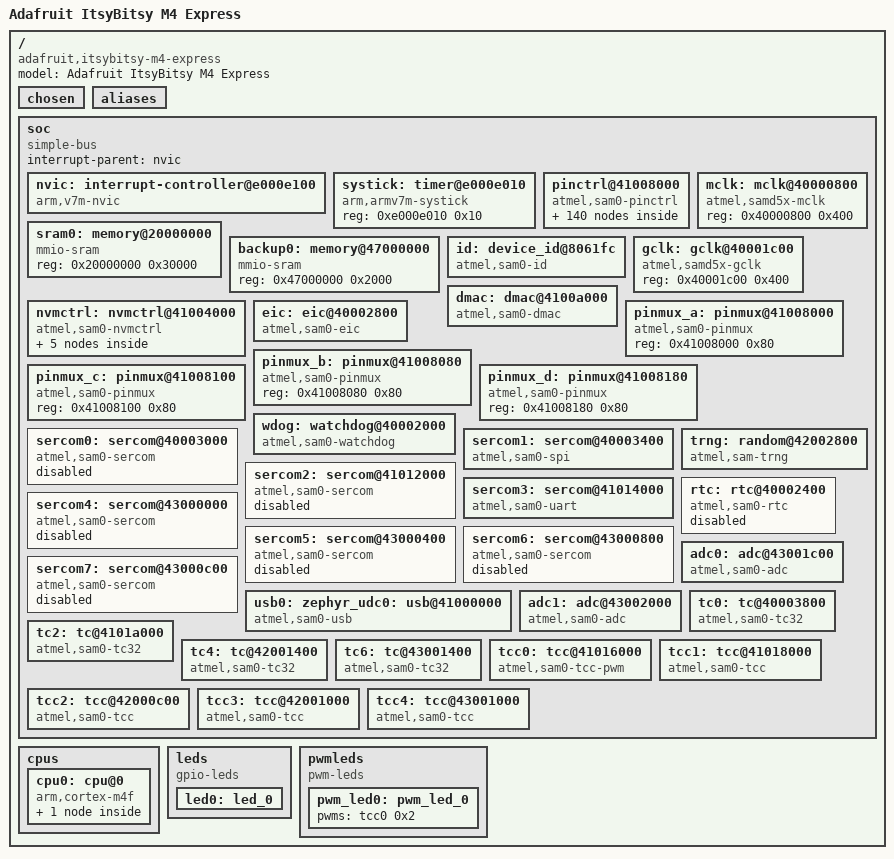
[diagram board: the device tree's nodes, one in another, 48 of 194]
/dts-v1/;

/ {
	#address-cells = < 0x1 >;
	#size-cells = < 0x1 >;
	model = "Adafruit ItsyBitsy M4 Express";
	compatible = "adafruit,itsybitsy-m4-express";
	chosen {
		zephyr,flash-controller = &nvmctrl;
		zephyr,entropy = &trng;
		zephyr,console = &sercom3;
		zephyr,shell-uart = &sercom3;
		zephyr,sram = &sram0;
		zephyr,flash = &flash0;
		zephyr,code-partition = &code_partition;
	};
	aliases {
		adc-0 = &adc0;
		adc-1 = &adc1;
		port-a = &porta;
		port-b = &portb;
		port-c = &portc;
		port-d = &portd;
		sercom-0 = &sercom0;
		sercom-1 = &sercom1;
		sercom-2 = &sercom2;
		sercom-3 = &sercom3;
		sercom-4 = &sercom4;
		sercom-5 = &sercom5;
		sercom-6 = &sercom6;
		sercom-7 = &sercom7;
		tc-0 = &tc0;
		tc-2 = &tc2;
		tc-4 = &tc4;
		tc-6 = &tc6;
		tcc-0 = &tcc0;
		tcc-1 = &tcc1;
		tcc-2 = &tcc2;
		tcc-3 = &tcc3;
		tcc-4 = &tcc4;
		watchdog0 = &wdog;
		led0 = &led0;
		pwm-led0 = &pwm_led0;
		pwm-0 = &tcc0;
	};
	soc {
		#address-cells = < 0x1 >;
		#size-cells = < 0x1 >;
		compatible = "simple-bus";
		interrupt-parent = < &nvic >;
		ranges;
		nvic: interrupt-controller@e000e100 {
			#address-cells = < 0x1 >;
			compatible = "arm,v7m-nvic";
			reg = < 0xe000e100 0xc00 >;
			interrupt-controller;
			#interrupt-cells = < 0x2 >;
			arm,num-irq-priority-bits = < 0x3 >;
			phandle = < 0x1 >;
		};
		systick: timer@e000e010 {
			compatible = "arm,armv7m-systick";
			reg = < 0xe000e010 0x10 >;
		};
		pinctrl@41008000 {
			compatible = "atmel,sam0-pinctrl";
			#address-cells = < 0x1 >;
			#size-cells = < 0x1 >;
			ranges = < 0x41008000 0x41008000 0x200 >;
			pa8c_sercom0_pad0: pa8c_sercom0_pad0 {
				atmel,pins = < &porta 0x8 0x2 >;
				pinmux-enable;
			};
			pa9c_sercom0_pad1: pa9c_sercom0_pad1 {
				atmel,pins = < &porta 0x9 0x2 >;
				pinmux-enable;
			};
			pa10c_sercom0_pad2: pa10c_sercom0_pad2 {
				atmel,pins = < &porta 0xa 0x2 >;
				pinmux-enable;
			};
			pa11c_sercom0_pad3: pa11c_sercom0_pad3 {
				atmel,pins = < &porta 0xb 0x2 >;
				pinmux-enable;
			};
			pb24c_sercom0_pad0: pb24c_sercom0_pad0 {
				atmel,pins = < &portb 0x18 0x2 >;
				pinmux-enable;
			};
			pb25c_sercom0_pad1: pb25c_sercom0_pad1 {
				atmel,pins = < &portb 0x19 0x2 >;
				pinmux-enable;
			};
			pc24c_sercom0_pad2: pc24c_sercom0_pad2 {
				atmel,pins = < &portc 0x18 0x2 >;
				pinmux-enable;
			};
			pc25c_sercom0_pad3: pc25c_sercom0_pad3 {
				atmel,pins = < &portc 0x19 0x2 >;
				pinmux-enable;
			};
			pa4d_sercom0_pad0: pa4d_sercom0_pad0 {
				atmel,pins = < &porta 0x4 0x3 >;
				pinmux-enable;
			};
			pa5d_sercom0_pad1: pa5d_sercom0_pad1 {
				atmel,pins = < &porta 0x5 0x3 >;
				pinmux-enable;
			};
			pa6d_sercom0_pad2: pa6d_sercom0_pad2 {
				atmel,pins = < &porta 0x6 0x3 >;
				pinmux-enable;
			};
			pa7d_sercom0_pad3: pa7d_sercom0_pad3 {
				atmel,pins = < &porta 0x7 0x3 >;
				pinmux-enable;
			};
			pc17d_sercom0_pad0: pc17d_sercom0_pad0 {
				atmel,pins = < &portc 0x11 0x3 >;
				pinmux-enable;
			};
			pc16d_sercom0_pad1: pc16d_sercom0_pad1 {
				atmel,pins = < &portc 0x10 0x3 >;
				pinmux-enable;
			};
			pc18d_sercom0_pad2: pc18d_sercom0_pad2 {
				atmel,pins = < &portc 0x12 0x3 >;
				pinmux-enable;
			};
			pc19d_sercom0_pad3: pc19d_sercom0_pad3 {
				atmel,pins = < &portc 0x13 0x3 >;
				pinmux-enable;
			};
			pa16c_sercom1_pad0: pa16c_sercom1_pad0 {
				atmel,pins = < &porta 0x10 0x2 >;
				pinmux-enable;
			};
			pa17c_sercom1_pad1: pa17c_sercom1_pad1 {
				atmel,pins = < &porta 0x11 0x2 >;
				pinmux-enable;
			};
			pa18c_sercom1_pad2: pa18c_sercom1_pad2 {
				atmel,pins = < &porta 0x12 0x2 >;
				pinmux-enable;
			};
			pa19c_sercom1_pad3: pa19c_sercom1_pad3 {
				atmel,pins = < &porta 0x13 0x2 >;
				pinmux-enable;
			};
			pc22c_sercom1_pad0: pc22c_sercom1_pad0 {
				atmel,pins = < &portc 0x16 0x2 >;
				pinmux-enable;
			};
			pc23c_sercom1_pad1: pc23c_sercom1_pad1 {
				atmel,pins = < &portc 0x17 0x2 >;
				pinmux-enable;
			};
			pd20c_sercom1_pad2: pd20c_sercom1_pad2 {
				atmel,pins = < &portd 0x14 0x2 >;
				pinmux-enable;
			};
			pd21c_sercom1_pad3: pd21c_sercom1_pad3 {
				atmel,pins = < &portd 0x15 0x2 >;
				pinmux-enable;
			};
			pc27c_sercom1_pad0: pc27c_sercom1_pad0 {
				atmel,pins = < &portc 0x1b 0x2 >;
				pinmux-enable;
			};
			pc28c_sercom1_pad1: pc28c_sercom1_pad1 {
				atmel,pins = < &portc 0x1c 0x2 >;
				pinmux-enable;
			};
			pb22c_sercom1_pad2: pb22c_sercom1_pad2 {
				atmel,pins = < &portb 0x16 0x2 >;
				pinmux-enable;
			};
			pb23c_sercom1_pad3: pb23c_sercom1_pad3 {
				atmel,pins = < &portb 0x17 0x2 >;
				pinmux-enable;
			};
			pa0d_sercom1_pad0: pa0d_sercom1_pad0 {
				atmel,pins = < &porta 0x0 0x3 >;
				pinmux-enable;
			};
			pa1d_sercom1_pad1: pa1d_sercom1_pad1 {
				atmel,pins = < &porta 0x1 0x3 >;
				pinmux-enable;
			};
			pa30d_sercom1_pad2: pa30d_sercom1_pad2 {
				atmel,pins = < &porta 0x1e 0x3 >;
				pinmux-enable;
			};
			pa31d_sercom1_pad3: pa31d_sercom1_pad3 {
				atmel,pins = < &porta 0x1f 0x3 >;
				pinmux-enable;
			};
			pa12c_sercom2_pad0: pa12c_sercom2_pad0 {
				atmel,pins = < &porta 0xc 0x2 >;
				pinmux-enable;
			};
			pa13c_sercom2_pad1: pa13c_sercom2_pad1 {
				atmel,pins = < &porta 0xd 0x2 >;
				pinmux-enable;
			};
			pa14c_sercom2_pad2: pa14c_sercom2_pad2 {
				atmel,pins = < &porta 0xe 0x2 >;
				pinmux-enable;
			};
			pa15c_sercom2_pad3: pa15c_sercom2_pad3 {
				atmel,pins = < &porta 0xf 0x2 >;
				pinmux-enable;
			};
			pb26c_sercom2_pad0: pb26c_sercom2_pad0 {
				atmel,pins = < &portb 0x1a 0x2 >;
				pinmux-enable;
			};
			pb27c_sercom2_pad1: pb27c_sercom2_pad1 {
				atmel,pins = < &portb 0x1b 0x2 >;
				pinmux-enable;
			};
			pb28c_sercom2_pad2: pb28c_sercom2_pad2 {
				atmel,pins = < &portb 0x1c 0x2 >;
				pinmux-enable;
			};
			pb29c_sercom2_pad3: pb29c_sercom2_pad3 {
				atmel,pins = < &portb 0x1d 0x2 >;
				pinmux-enable;
			};
			pa8d_sercom2_pad0: pa8d_sercom2_pad0 {
				atmel,pins = < &porta 0x8 0x3 >;
				pinmux-enable;
			};
			pa9d_sercom2_pad1: pa9d_sercom2_pad1 {
				atmel,pins = < &porta 0x9 0x3 >;
				pinmux-enable;
			};
			pa10d_sercom2_pad2: pa10d_sercom2_pad2 {
				atmel,pins = < &porta 0xa 0x3 >;
				pinmux-enable;
			};
			pa11d_sercom2_pad3: pa11d_sercom2_pad3 {
				atmel,pins = < &porta 0xb 0x3 >;
				pinmux-enable;
			};
			pb24d_sercom2_pad0: pb24d_sercom2_pad0 {
				atmel,pins = < &portb 0x18 0x3 >;
				pinmux-enable;
			};
			pb25d_sercom2_pad1: pb25d_sercom2_pad1 {
				atmel,pins = < &portb 0x19 0x3 >;
				pinmux-enable;
			};
			pc24d_sercom2_pad2: pc24d_sercom2_pad2 {
				atmel,pins = < &portc 0x18 0x3 >;
				pinmux-enable;
			};
			pc25d_sercom2_pad3: pc25d_sercom2_pad3 {
				atmel,pins = < &portc 0x19 0x3 >;
				pinmux-enable;
			};
			pa22c_sercom3_pad0: pa22c_sercom3_pad0 {
				atmel,pins = < &porta 0x16 0x2 >;
				pinmux-enable;
			};
			pa23c_sercom3_pad1: pa23c_sercom3_pad1 {
				atmel,pins = < &porta 0x17 0x2 >;
				pinmux-enable;
			};
			pa24c_sercom3_pad2: pa24c_sercom3_pad2 {
				atmel,pins = < &porta 0x18 0x2 >;
				pinmux-enable;
			};
			pa25c_sercom3_pad3: pa25c_sercom3_pad3 {
				atmel,pins = < &porta 0x19 0x2 >;
				pinmux-enable;
			};
			pb20c_sercom3_pad0: pb20c_sercom3_pad0 {
				atmel,pins = < &portb 0x14 0x2 >;
				pinmux-enable;
			};
			pb21c_sercom3_pad1: pb21c_sercom3_pad1 {
				atmel,pins = < &portb 0x15 0x2 >;
				pinmux-enable;
			};
			pa20d_sercom3_pad2: pa20d_sercom3_pad2 {
				atmel,pins = < &porta 0x14 0x3 >;
				pinmux-enable;
			};
			pa21d_sercom3_pad3: pa21d_sercom3_pad3 {
				atmel,pins = < &porta 0x15 0x3 >;
				pinmux-enable;
			};
			pa17d_sercom3_pad0: pa17d_sercom3_pad0 {
				atmel,pins = < &porta 0x11 0x3 >;
				pinmux-enable;
				phandle = < 0x9 >;
			};
			pa16d_sercom3_pad1: pa16d_sercom3_pad1 {
				atmel,pins = < &porta 0x10 0x3 >;
				pinmux-enable;
				phandle = < 0x8 >;
			};
			pa18d_sercom3_pad2: pa18d_sercom3_pad2 {
				atmel,pins = < &porta 0x12 0x3 >;
				pinmux-enable;
			};
			pa19d_sercom3_pad3: pa19d_sercom3_pad3 {
				atmel,pins = < &porta 0x13 0x3 >;
				pinmux-enable;
			};
			pc23d_sercom3_pad0: pc23d_sercom3_pad0 {
				atmel,pins = < &portc 0x17 0x3 >;
				pinmux-enable;
			};
			pc22d_sercom3_pad1: pc22d_sercom3_pad1 {
				atmel,pins = < &portc 0x16 0x3 >;
				pinmux-enable;
			};
			pd20d_sercom3_pad2: pd20d_sercom3_pad2 {
				atmel,pins = < &portd 0x14 0x3 >;
				pinmux-enable;
			};
			pd21d_sercom3_pad3: pd21d_sercom3_pad3 {
				atmel,pins = < &portd 0x15 0x3 >;
				pinmux-enable;
			};
			pb12c_sercom4_pad0: pb12c_sercom4_pad0 {
				atmel,pins = < &portb 0xc 0x2 >;
				pinmux-enable;
			};
			pb13c_sercom4_pad1: pb13c_sercom4_pad1 {
				atmel,pins = < &portb 0xd 0x2 >;
				pinmux-enable;
			};
			pb14c_sercom4_pad2: pb14c_sercom4_pad2 {
				atmel,pins = < &portb 0xe 0x2 >;
				pinmux-enable;
			};
			pb15c_sercom4_pad3: pb15c_sercom4_pad3 {
				atmel,pins = < &portb 0xf 0x2 >;
				pinmux-enable;
			};
			pb8d_sercom4_pad0: pb8d_sercom4_pad0 {
				atmel,pins = < &portb 0x8 0x3 >;
				pinmux-enable;
			};
			pb9d_sercom4_pad1: pb9d_sercom4_pad1 {
				atmel,pins = < &portb 0x9 0x3 >;
				pinmux-enable;
			};
			pb10d_sercom4_pad2: pb10d_sercom4_pad2 {
				atmel,pins = < &portb 0xa 0x3 >;
				pinmux-enable;
			};
			pb11d_sercom4_pad3: pb11d_sercom4_pad3 {
				atmel,pins = < &portb 0xb 0x3 >;
				pinmux-enable;
			};
			pa13d_sercom4_pad0: pa13d_sercom4_pad0 {
				atmel,pins = < &porta 0xd 0x3 >;
				pinmux-enable;
			};
			pa12d_sercom4_pad1: pa12d_sercom4_pad1 {
				atmel,pins = < &porta 0xc 0x3 >;
				pinmux-enable;
			};
			pa14d_sercom4_pad2: pa14d_sercom4_pad2 {
				atmel,pins = < &porta 0xe 0x3 >;
				pinmux-enable;
			};
			pa15d_sercom4_pad3: pa15d_sercom4_pad3 {
				atmel,pins = < &porta 0xf 0x3 >;
				pinmux-enable;
			};
			pb27d_sercom4_pad0: pb27d_sercom4_pad0 {
				atmel,pins = < &portb 0x1b 0x3 >;
				pinmux-enable;
			};
			pb26d_sercom4_pad1: pb26d_sercom4_pad1 {
				atmel,pins = < &portb 0x1a 0x3 >;
				pinmux-enable;
			};
			pb28d_sercom4_pad2: pb28d_sercom4_pad2 {
				atmel,pins = < &portb 0x1c 0x3 >;
				pinmux-enable;
			};
			pb29d_sercom4_pad3: pb29d_sercom4_pad3 {
				atmel,pins = < &portb 0x1d 0x3 >;
				pinmux-enable;
			};
			pb16c_sercom5_pad0: pb16c_sercom5_pad0 {
				atmel,pins = < &portb 0x10 0x2 >;
				pinmux-enable;
			};
			pb17c_sercom5_pad1: pb17c_sercom5_pad1 {
				atmel,pins = < &portb 0x11 0x2 >;
				pinmux-enable;
			};
			pb18c_sercom5_pad2: pb18c_sercom5_pad2 {
				atmel,pins = < &portb 0x12 0x2 >;
				pinmux-enable;
			};
			pb19c_sercom5_pad3: pb19c_sercom5_pad3 {
				atmel,pins = < &portb 0x13 0x2 >;
				pinmux-enable;
			};
			pa23d_sercom5_pad0: pa23d_sercom5_pad0 {
				atmel,pins = < &porta 0x17 0x3 >;
				pinmux-enable;
			};
			pa22d_sercom5_pad1: pa22d_sercom5_pad1 {
				atmel,pins = < &porta 0x16 0x3 >;
				pinmux-enable;
			};
			pa20c_sercom5_pad2: pa20c_sercom5_pad2 {
				atmel,pins = < &porta 0x14 0x2 >;
				pinmux-enable;
			};
			pa21c_sercom5_pad3: pa21c_sercom5_pad3 {
				atmel,pins = < &porta 0x15 0x2 >;
				pinmux-enable;
			};
			pa24d_sercom5_pad2: pa24d_sercom5_pad2 {
				atmel,pins = < &porta 0x18 0x3 >;
				pinmux-enable;
			};
			pa25d_sercom5_pad3: pa25d_sercom5_pad3 {
				atmel,pins = < &porta 0x19 0x3 >;
				pinmux-enable;
			};
			pb22d_sercom5_pad2: pb22d_sercom5_pad2 {
				atmel,pins = < &portb 0x16 0x3 >;
				pinmux-enable;
			};
			pb23d_sercom5_pad3: pb23d_sercom5_pad3 {
				atmel,pins = < &portb 0x17 0x3 >;
				pinmux-enable;
			};
			pb31d_sercom5_pad0: pb31d_sercom5_pad0 {
				atmel,pins = < &portb 0x1f 0x3 >;
				pinmux-enable;
			};
			pb30d_sercom5_pad1: pb30d_sercom5_pad1 {
				atmel,pins = < &portb 0x1e 0x3 >;
				pinmux-enable;
			};
			pb0d_sercom5_pad2: pb0d_sercom5_pad2 {
				atmel,pins = < &portb 0x0 0x3 >;
				pinmux-enable;
			};
			pb1d_sercom5_pad3: pb1d_sercom5_pad3 {
				atmel,pins = < &portb 0x1 0x3 >;
				pinmux-enable;
			};
			pb2d_sercom5_pad0: pb2d_sercom5_pad0 {
				atmel,pins = < &portb 0x2 0x3 >;
				pinmux-enable;
			};
			pb3d_sercom5_pad1: pb3d_sercom5_pad1 {
				atmel,pins = < &portb 0x3 0x3 >;
				pinmux-enable;
			};
			pc16c_sercom6_pad0: pc16c_sercom6_pad0 {
				atmel,pins = < &portc 0x10 0x2 >;
				pinmux-enable;
			};
			pc17c_sercom6_pad1: pc17c_sercom6_pad1 {
				atmel,pins = < &portc 0x11 0x2 >;
				pinmux-enable;
			};
			pc18c_sercom6_pad2: pc18c_sercom6_pad2 {
				atmel,pins = < &portc 0x12 0x2 >;
				pinmux-enable;
			};
			pc19c_sercom6_pad3: pc19c_sercom6_pad3 {
				atmel,pins = < &portc 0x13 0x2 >;
				pinmux-enable;
			};
			pc4c_sercom6_pad0: pc4c_sercom6_pad0 {
				atmel,pins = < &portc 0x4 0x2 >;
				pinmux-enable;
			};
			pc5c_sercom6_pad1: pc5c_sercom6_pad1 {
				atmel,pins = < &portc 0x5 0x2 >;
				pinmux-enable;
			};
			pc6c_sercom6_pad2: pc6c_sercom6_pad2 {
				atmel,pins = < &portc 0x6 0x2 >;
				pinmux-enable;
			};
			pc7c_sercom6_pad3: pc7c_sercom6_pad3 {
				atmel,pins = < &portc 0x7 0x2 >;
				pinmux-enable;
			};
			pd9d_sercom6_pad0: pd9d_sercom6_pad0 {
				atmel,pins = < &portd 0x9 0x3 >;
				pinmux-enable;
			};
			pd8d_sercom6_pad1: pd8d_sercom6_pad1 {
				atmel,pins = < &portd 0x8 0x3 >;
				pinmux-enable;
			};
			pd10d_sercom6_pad2: pd10d_sercom6_pad2 {
				atmel,pins = < &portd 0xa 0x3 >;
				pinmux-enable;
			};
			pd11d_sercom6_pad3: pd11d_sercom6_pad3 {
				atmel,pins = < &portd 0xb 0x3 >;
				pinmux-enable;
			};
			pc13d_sercom6_pad0: pc13d_sercom6_pad0 {
				atmel,pins = < &portc 0xd 0x3 >;
				pinmux-enable;
			};
			pc12d_sercom6_pad1: pc12d_sercom6_pad1 {
				atmel,pins = < &portc 0xc 0x3 >;
				pinmux-enable;
			};
			pc14d_sercom6_pad2: pc14d_sercom6_pad2 {
				atmel,pins = < &portc 0xe 0x3 >;
				pinmux-enable;
			};
			pc15d_sercom6_pad3: pc15d_sercom6_pad3 {
				atmel,pins = < &portc 0xf 0x3 >;
				pinmux-enable;
			};
			pc10c_sercom6_pad2: pc10c_sercom6_pad2 {
				atmel,pins = < &portc 0xa 0x2 >;
				pinmux-enable;
			};
			pc11c_sercom6_pad3: pc11c_sercom6_pad3 {
				atmel,pins = < &portc 0xb 0x2 >;
				pinmux-enable;
			};
			pc12c_sercom7_pad0: pc12c_sercom7_pad0 {
				atmel,pins = < &portc 0xc 0x2 >;
				pinmux-enable;
			};
			pc13c_sercom7_pad1: pc13c_sercom7_pad1 {
				atmel,pins = < &portc 0xd 0x2 >;
				pinmux-enable;
			};
			pc14c_sercom7_pad2: pc14c_sercom7_pad2 {
				atmel,pins = < &portc 0xe 0x2 >;
				pinmux-enable;
			};
			pc15c_sercom7_pad3: pc15c_sercom7_pad3 {
				atmel,pins = < &portc 0xf 0x2 >;
				pinmux-enable;
			};
			pd8c_sercom7_pad0: pd8c_sercom7_pad0 {
				atmel,pins = < &portd 0x8 0x2 >;
				pinmux-enable;
			};
			pd9c_sercom7_pad1: pd9c_sercom7_pad1 {
				atmel,pins = < &portd 0x9 0x2 >;
				pinmux-enable;
			};
			pd10c_sercom7_pad2: pd10c_sercom7_pad2 {
				atmel,pins = < &portd 0xa 0x2 >;
				pinmux-enable;
			};
			pd11c_sercom7_pad3: pd11c_sercom7_pad3 {
				atmel,pins = < &portd 0xb 0x2 >;
				pinmux-enable;
			};
			pc12d_sercom7_pad0: pc12d_sercom7_pad0 {
				atmel,pins = < &portc 0xc 0x3 >;
				pinmux-enable;
			};
			pc13d_sercom7_pad1: pc13d_sercom7_pad1 {
				atmel,pins = < &portc 0xd 0x3 >;
				pinmux-enable;
			};
			pc10d_sercom7_pad2: pc10d_sercom7_pad2 {
				atmel,pins = < &portc 0xa 0x3 >;
				pinmux-enable;
			};
			pc11d_sercom7_pad3: pc11d_sercom7_pad3 {
				atmel,pins = < &portc 0xb 0x3 >;
				pinmux-enable;
			};
			pb21d_sercom7_pad0: pb21d_sercom7_pad0 {
				atmel,pins = < &portb 0x15 0x3 >;
				pinmux-enable;
			};
			pb20d_sercom7_pad1: pb20d_sercom7_pad1 {
				atmel,pins = < &portb 0x14 0x3 >;
				pinmux-enable;
			};
			pb18d_sercom7_pad2: pb18d_sercom7_pad2 {
				atmel,pins = < &portb 0x12 0x3 >;
				pinmux-enable;
			};
			pb19d_sercom7_pad3: pb19d_sercom7_pad3 {
				atmel,pins = < &portb 0x13 0x3 >;
				pinmux-enable;
			};
			pb30d_sercom7_pad0: pb30d_sercom7_pad0 {
				atmel,pins = < &portb 0x1e 0x3 >;
				pinmux-enable;
			};
			pb31d_sercom7_pad1: pb31d_sercom7_pad1 {
				atmel,pins = < &portb 0x1f 0x3 >;
				pinmux-enable;
			};
			pa30d_sercom7_pad2: pa30d_sercom7_pad2 {
				atmel,pins = < &porta 0x1e 0x3 >;
				pinmux-enable;
			};
			pa31d_sercom7_pad3: pa31d_sercom7_pad3 {
				atmel,pins = < &porta 0x1f 0x3 >;
				pinmux-enable;
			};
			porta: gpio@41008000 {
				compatible = "atmel,sam0-gpio";
				reg = < 0x41008000 0x80 >;
				label = "PORTA";
				gpio-controller;
				#gpio-cells = < 0x2 >;
				#atmel,pin-cells = < 0x2 >;
				phandle = < 0x2 >;
			};
			portb: gpio@41008080 {
				compatible = "atmel,sam0-gpio";
				reg = < 0x41008080 0x80 >;
				label = "PORTB";
				gpio-controller;
				#gpio-cells = < 0x2 >;
				#atmel,pin-cells = < 0x2 >;
				phandle = < 0x3 >;
			};
			portc: gpio@41008100 {
				compatible = "atmel,sam0-gpio";
				reg = < 0x41008100 0x80 >;
				label = "PORTC";
				gpio-controller;
				#gpio-cells = < 0x2 >;
				#atmel,pin-cells = < 0x2 >;
				phandle = < 0x4 >;
			};
			portd: gpio@41008180 {
				compatible = "atmel,sam0-gpio";
				reg = < 0x41008180 0x80 >;
				label = "PORTD";
				gpio-controller;
				#gpio-cells = < 0x2 >;
				#atmel,pin-cells = < 0x2 >;
				phandle = < 0x5 >;
			};
		};
		sram0: memory@20000000 {
			compatible = "mmio-sram";
			reg = < 0x20000000 0x30000 >;
		};
		backup0: memory@47000000 {
			compatible = "mmio-sram";
			reg = < 0x47000000 0x2000 >;
		};
		id: device_id@8061fc {
			compatible = "atmel,sam0-id";
			reg = < 0x8061fc 0x4 >, < 0x806010 0x4 >, < 0x806014 0x4 >, < 0x806018 0x4 >;
		};
		mclk: mclk@40000800 {
			compatible = "atmel,samd5x-mclk";
			reg = < 0x40000800 0x400 >;
			#clock-cells = < 0x2 >;
			phandle = < 0x7 >;
		};
		gclk: gclk@40001c00 {
			compatible = "atmel,samd5x-gclk";
			reg = < 0x40001c00 0x400 >;
			#clock-cells = < 0x1 >;
			phandle = < 0x6 >;
		};
		nvmctrl: nvmctrl@41004000 {
			compatible = "atmel,sam0-nvmctrl";
			label = "FLASH_CTRL";
			reg = < 0x41004000 0x22 >;
			interrupts = < 0x1d 0x0 >, < 0x1e 0x0 >;
			lock-regions = < 0x20 >;
			#address-cells = < 0x1 >;
			#size-cells = < 0x1 >;
			flash0: flash@0 {
				compatible = "soc-nv-flash";
				label = "FLASH_0";
				write-block-size = < 0x8 >;
				reg = < 0x0 0x80000 >;
				partitions {
					compatible = "fixed-partitions";
					#address-cells = < 0x1 >;
					#size-cells = < 0x1 >;
					boot_partition: partition@0 {
						label = "uf2";
						reg = < 0x0 0x4000 >;
						read-only;
					};
					code_partition: partition@4000 {
						label = "code";
						reg = < 0x4000 0x78000 >;
						read-only;
					};
					storage_partition: partition@7c000 {
						label = "storage";
						reg = < 0x7c000 0x4000 >;
					};
				};
			};
		};
		dmac: dmac@4100a000 {
			compatible = "atmel,sam0-dmac";
			reg = < 0x4100a000 0x50 >;
			interrupts = < 0x1f 0x0 >, < 0x20 0x0 >, < 0x21 0x0 >, < 0x22 0x0 >, < 0x23 0x0 >;
			label = "DMA_0";
			#dma-cells = < 0x2 >;
			status = "okay";
		};
		eic: eic@40002800 {
			compatible = "atmel,sam0-eic";
			reg = < 0x40002800 0x38 >;
			interrupts = < 0xc 0x0 >, < 0xd 0x0 >, < 0xe 0x0 >, < 0xf 0x0 >, < 0x10 0x0 >, < 0x11 0x0 >, < 0x12 0x0 >, < 0x13 0x0 >, < 0x14 0x0 >, < 0x15 0x0 >, < 0x16 0x0 >, < 0x17 0x0 >, < 0x18 0x0 >, < 0x19 0x0 >, < 0x1a 0x0 >, < 0x1b 0x0 >;
			label = "EIC";
		};
		pinmux_a: pinmux@41008000 {
			compatible = "atmel,sam0-pinmux";
			reg = < 0x41008000 0x80 >;
		};
		pinmux_b: pinmux@41008080 {
			compatible = "atmel,sam0-pinmux";
			reg = < 0x41008080 0x80 >;
		};
		pinmux_c: pinmux@41008100 {
			compatible = "atmel,sam0-pinmux";
			reg = < 0x41008100 0x80 >;
		};
		pinmux_d: pinmux@41008180 {
			compatible = "atmel,sam0-pinmux";
			reg = < 0x41008180 0x80 >;
		};
		wdog: watchdog@40002000 {
			compatible = "atmel,sam0-watchdog";
			reg = < 0x40002000 0xd >;
			interrupts = < 0xa 0x0 >;
			label = "WATCHDOG_0";
		};
		sercom0: sercom@40003000 {
			compatible = "atmel,sam0-sercom";
			reg = < 0x40003000 0x40 >;
			interrupts = < 0x2e 0x0 >, < 0x2f 0x0 >, < 0x30 0x0 >, < 0x31 0x0 >;
			status = "disabled";
			label = "SERCOM0";
			clocks = < &gclk 0x7 >, < &mclk 0x14 0xc >;
			clock-names = "GCLK", "MCLK";
		};
		sercom1: sercom@40003400 {
			compatible = "atmel,sam0-spi";
			reg = < 0x40003400 0x40 >;
			interrupts = < 0x32 0x0 >, < 0x33 0x0 >, < 0x34 0x0 >, < 0x35 0x0 >;
			status = "okay";
			label = "SERCOM1";
			clocks = < &gclk 0x8 >, < &mclk 0x14 0xd >;
			clock-names = "GCLK", "MCLK";
			dipo = < 0x3 >;
			dopo = < 0x0 >;
			#address-cells = < 0x1 >;
			#size-cells = < 0x0 >;
		};
		sercom2: sercom@41012000 {
			compatible = "atmel,sam0-sercom";
			reg = < 0x41012000 0x40 >;
			interrupts = < 0x36 0x0 >, < 0x37 0x0 >, < 0x38 0x0 >, < 0x39 0x0 >;
			status = "disabled";
			label = "SERCOM2";
			clocks = < &gclk 0x17 >, < &mclk 0x18 0x9 >;
			clock-names = "GCLK", "MCLK";
		};
		sercom3: sercom@41014000 {
			compatible = "atmel,sam0-uart";
			reg = < 0x41014000 0x40 >;
			interrupts = < 0x3a 0x0 >, < 0x3b 0x0 >, < 0x3c 0x0 >, < 0x3d 0x0 >;
			status = "okay";
			label = "SERCOM3";
			clocks = < &gclk 0x18 >, < &mclk 0x18 0xa >;
			clock-names = "GCLK", "MCLK";
			current-speed = < 0x1c200 >;
			rxpo = < 0x1 >;
			txpo = < 0x0 >;
			pinctrl-0 = < &pa16d_sercom3_pad1 &pa17d_sercom3_pad0 >;
		};
		sercom4: sercom@43000000 {
			compatible = "atmel,sam0-sercom";
			reg = < 0x43000000 0x40 >;
			interrupts = < 0x3e 0x0 >, < 0x3f 0x0 >, < 0x40 0x0 >, < 0x41 0x0 >;
			status = "disabled";
			label = "SERCOM4";
			clocks = < &gclk 0x22 >, < &mclk 0x20 0x0 >;
			clock-names = "GCLK", "MCLK";
		};
		sercom5: sercom@43000400 {
			compatible = "atmel,sam0-sercom";
			reg = < 0x43000400 0x40 >;
			interrupts = < 0x42 0x0 >, < 0x43 0x0 >, < 0x44 0x0 >, < 0x45 0x0 >;
			status = "disabled";
			label = "SERCOM5";
			clocks = < &gclk 0x23 >, < &mclk 0x20 0x1 >;
			clock-names = "GCLK", "MCLK";
		};
		sercom6: sercom@43000800 {
			compatible = "atmel,sam0-sercom";
			reg = < 0x43000800 0x40 >;
			interrupts = < 0x46 0x0 >, < 0x47 0x0 >, < 0x48 0x0 >, < 0x49 0x0 >;
			status = "disabled";
			label = "SERCOM6";
			clocks = < &gclk 0x24 >, < &mclk 0x20 0x2 >;
			clock-names = "GCLK", "MCLK";
		};
		sercom7: sercom@43000c00 {
			compatible = "atmel,sam0-sercom";
			reg = < 0x43000c00 0x40 >;
			interrupts = < 0x4a 0x0 >, < 0x4b 0x0 >, < 0x4c 0x0 >, < 0x4d 0x0 >;
			status = "disabled";
			label = "SERCOM7";
			clocks = < &gclk 0x25 >, < &mclk 0x20 0x3 >;
			clock-names = "GCLK", "MCLK";
		};
		usb0: zephyr_udc0: usb@41000000 {
			compatible = "atmel,sam0-usb";
			status = "okay";
			reg = < 0x41000000 0x1000 >;
			interrupts = < 0x50 0x0 >, < 0x51 0x0 >, < 0x52 0x0 >, < 0x53 0x0 >;
			num-bidir-endpoints = < 0x8 >;
			label = "USB0";
		};
		trng: random@42002800 {
			compatible = "atmel,sam-trng";
			reg = < 0x42002800 0x1e >;
			peripheral-id = < 0x0 >;
			interrupts = < 0x83 0x0 >;
			label = "ENTROPY_0";
		};
		rtc: rtc@40002400 {
			compatible = "atmel,sam0-rtc";
			reg = < 0x40002400 0x1c >;
			interrupts = < 0xb 0x0 >;
			clock-generator = < 0x0 >;
			status = "disabled";
			label = "RTC";
		};
		adc0: adc@43001c00 {
			compatible = "atmel,sam0-adc";
			reg = < 0x43001c00 0x4a >;
			interrupts = < 0x76 0x0 >, < 0x77 0x0 >;
			interrupt-names = "overrun", "resrdy";
			label = "ADC_0";
			gclk = < 0x2 >;
			prescaler = < 0x4 >;
			#io-channel-cells = < 0x1 >;
			clocks = < &gclk 0x28 >, < &mclk 0x20 0x7 >;
			clock-names = "GCLK", "MCLK";
			calib-offset = < 0x0 >;
		};
		adc1: adc@43002000 {
			compatible = "atmel,sam0-adc";
			reg = < 0x43002000 0x4a >;
			interrupts = < 0x78 0x0 >, < 0x79 0x0 >;
			interrupt-names = "overrun", "resrdy";
			label = "ADC_1";
			gclk = < 0x2 >;
			prescaler = < 0x4 >;
			#io-channel-cells = < 0x1 >;
			clocks = < &gclk 0x29 >, < &mclk 0x20 0x8 >;
			clock-names = "GCLK", "MCLK";
			calib-offset = < 0xe >;
		};
		tc0: tc@40003800 {
			compatible = "atmel,sam0-tc32";
			reg = < 0x40003800 0x34 >;
			interrupts = < 0x6b 0x0 >;
			label = "TIMER_0";
			clocks = < &gclk 0x9 >, < &mclk 0x14 0xe >;
			clock-names = "GCLK", "MCLK";
		};
		tc2: tc@4101a000 {
			compatible = "atmel,sam0-tc32";
			reg = < 0x4101a000 0x34 >;
			interrupts = < 0x6d 0x0 >;
			label = "TIMER_2";
			clocks = < &gclk 0x1a >, < &mclk 0x18 0xd >;
			clock-names = "GCLK", "MCLK";
		};
		tc4: tc@42001400 {
			compatible = "atmel,sam0-tc32";
			reg = < 0x42001400 0x34 >;
			interrupts = < 0x6f 0x0 >;
			label = "TIMER_4";
			clocks = < &gclk 0x1e >, < &mclk 0x1c 0x5 >;
			clock-names = "GCLK", "MCLK";
		};
		tc6: tc@43001400 {
			compatible = "atmel,sam0-tc32";
			reg = < 0x43001400 0x34 >;
			interrupts = < 0x71 0x0 >;
			label = "TIMER_6";
			clocks = < &gclk 0x27 >, < &mclk 0x20 0x5 >;
			clock-names = "GCLK", "MCLK";
		};
		tcc0: tcc@41016000 {
			compatible = "atmel,sam0-tcc-pwm";
			reg = < 0x41016000 0x2000 >;
			interrupts = < 0x55 0x0 >, < 0x56 0x0 >, < 0x57 0x0 >, < 0x58 0x0 >, < 0x59 0x0 >, < 0x5a 0x0 >, < 0x5b 0x0 >;
			label = "TCC_0";
			clocks = < &gclk 0x19 >, < &mclk 0x18 0xb >;
			clock-names = "GCLK", "MCLK";
			channels = < 0x6 >;
			counter-size = < 0x18 >;
			status = "okay";
			prescaler = < 0x8 >;
			#pwm-cells = < 0x1 >;
			phandle = < 0xa >;
		};
		tcc1: tcc@41018000 {
			compatible = "atmel,sam0-tcc";
			reg = < 0x41018000 0x2000 >;
			interrupts = < 0x5c 0x0 >, < 0x5d 0x0 >, < 0x5e 0x0 >, < 0x5f 0x0 >, < 0x60 0x0 >;
			label = "TCC_1";
			clocks = < &gclk 0x19 >, < &mclk 0x18 0xc >;
			clock-names = "GCLK", "MCLK";
			channels = < 0x4 >;
			counter-size = < 0x18 >;
		};
		tcc2: tcc@42000c00 {
			compatible = "atmel,sam0-tcc";
			reg = < 0x42000c00 0x400 >;
			interrupts = < 0x61 0x0 >, < 0x62 0x0 >, < 0x63 0x0 >, < 0x64 0x0 >;
			label = "TCC_2";
			clocks = < &gclk 0x1d >, < &mclk 0x1c 0x3 >;
			clock-names = "GCLK", "MCLK";
			channels = < 0x3 >;
			counter-size = < 0x10 >;
		};
		tcc3: tcc@42001000 {
			compatible = "atmel,sam0-tcc";
			reg = < 0x42001000 0x400 >;
			interrupts = < 0x65 0x0 >, < 0x66 0x0 >, < 0x67 0x0 >;
			label = "TCC_3";
			clocks = < &gclk 0x1d >, < &mclk 0x1c 0x4 >;
			clock-names = "GCLK", "MCLK";
			channels = < 0x2 >;
			counter-size = < 0x10 >;
		};
		tcc4: tcc@43001000 {
			compatible = "atmel,sam0-tcc";
			reg = < 0x43001000 0x400 >;
			interrupts = < 0x68 0x0 >, < 0x69 0x0 >, < 0x6a 0x0 >;
			label = "TCC_4";
			clocks = < &gclk 0x26 >, < &mclk 0x20 0x4 >;
			clock-names = "GCLK", "MCLK";
			channels = < 0x2 >;
			counter-size = < 0x10 >;
		};
	};
	cpus {
		#address-cells = < 0x1 >;
		#size-cells = < 0x0 >;
		cpu0: cpu@0 {
			device_type = "cpu";
			compatible = "arm,cortex-m4f";
			reg = < 0x0 >;
			#address-cells = < 0x1 >;
			#size-cells = < 0x1 >;
			clock-frequency = < 0x7270e00 >;
			mpu: mpu@e000ed90 {
				compatible = "arm,armv7m-mpu";
				reg = < 0xe000ed90 0x40 >;
				arm,num-mpu-regions = < 0x8 >;
			};
		};
	};
	leds {
		compatible = "gpio-leds";
		led0: led_0 {
			gpios = < &porta 0x16 0x0 >;
			label = "LED";
		};
	};
	pwmleds {
		compatible = "pwm-leds";
		pwm_led0: pwm_led_0 {
			pwms = < &tcc0 0x2 >;
		};
	};
};
